VERSION ""

NS_ :

BS_:

BU_: VCU BMS Motor1 Motor2 CCU SCG

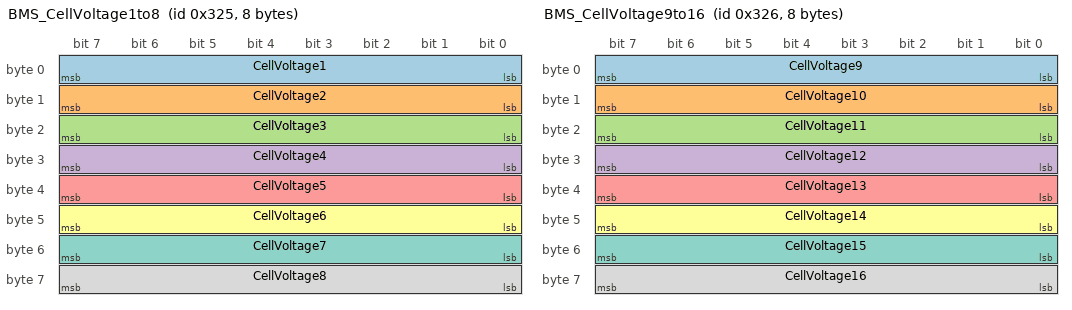
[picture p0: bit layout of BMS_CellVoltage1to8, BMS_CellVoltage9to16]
BO_ 805 BMS_CellVoltage1to8: 8 BMS
 SG_ CellVoltage1 : 0|8@1+ (0.02,0) [0|4.5] "" Vector__XXX
 SG_ CellVoltage2 : 8|8@1+ (0.02,0) [0|4.5] "" Vector__XXX
 SG_ CellVoltage3 : 16|8@1+ (0.02,0) [0|4.5] "" Vector__XXX
 SG_ CellVoltage4 : 24|8@1+ (0.02,0) [0|4.5] "" Vector__XXX
 SG_ CellVoltage5 : 32|8@1+ (0.02,0) [0|4.5] "" Vector__XXX
 SG_ CellVoltage6 : 40|8@1+ (0.02,0) [0|4.5] "" Vector__XXX
 SG_ CellVoltage7 : 48|8@1+ (0.02,0) [0|4.5] "" Vector__XXX
 SG_ CellVoltage8 : 56|8@1+ (0.02,0) [0|4.5] "" Vector__XXX

BO_ 806 BMS_CellVoltage9to16: 8 BMS
 SG_ CellVoltage9 : 0|8@1+ (0.02,0) [0|4.5] "" Vector__XXX
 SG_ CellVoltage10 : 8|8@1+ (0.02,0) [0|4.5] "" Vector__XXX
 SG_ CellVoltage11 : 16|8@1+ (0.02,0) [0|4.5] "" Vector__XXX
 SG_ CellVoltage12 : 24|8@1+ (0.02,0) [0|4.5] "" Vector__XXX
 SG_ CellVoltage13 : 32|8@1+ (0.02,0) [0|4.5] "" Vector__XXX
 SG_ CellVoltage14 : 40|8@1+ (0.02,0) [0|4.5] "" Vector__XXX
 SG_ CellVoltage15 : 48|8@1+ (0.02,0) [0|4.5] "" Vector__XXX
 SG_ CellVoltage16 : 56|8@1+ (0.02,0) [0|4.5] "" Vector__XXX

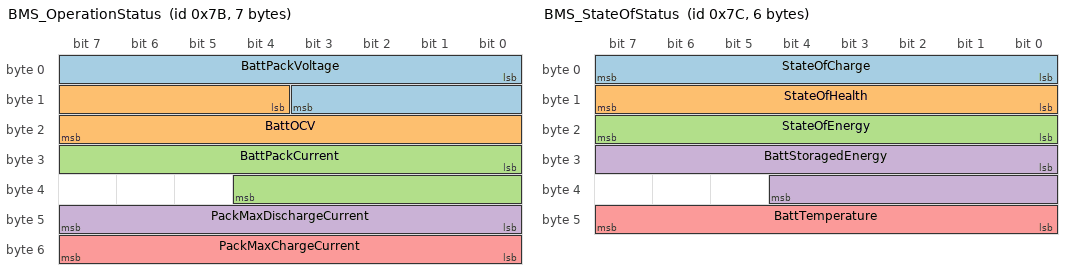
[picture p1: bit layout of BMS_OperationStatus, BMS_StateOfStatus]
BO_ 123 BMS_OperationStatus: 7 BMS
 SG_ BattPackVoltage : 0|12@1+ (0.02,0) [0|60] "V" Vector__XXX
 SG_ BattOCV : 12|12@1+ (0.02,0) [0|60] "V" Vector__XXX
 SG_ BattPackCurrent : 24|13@1+ (0.1,-409.6) [-250|250] "A" Vector__XXX
 SG_ PackMaxDischargeCurrent : 40|8@1+ (1,0) [0|250] "A" Vector__XXX
 SG_ PackMaxChargeCurrent : 48|8@1+ (1,0) [0|250] "A" Vector__XXX

BO_ 124 BMS_StateOfStatus: 6 BMS
 SG_ StateOfCharge : 0|8@1+ (0.5,0) [0|100] "%" Vector__XXX
 SG_ StateOfHealth : 8|8@1+ (0.5,0) [0|100] "%" Vector__XXX
 SG_ StateOfEnergy : 16|8@1+ (0.5,0) [0|100] "%" Vector__XXX
 SG_ BattStoragedEnergy : 24|13@1+ (1,0) [0|6000] "kWh" Vector__XXX
 SG_ BattTemperature : 40|8@1+ (0.5,-10) [-10|100] "%" Vector__XXX

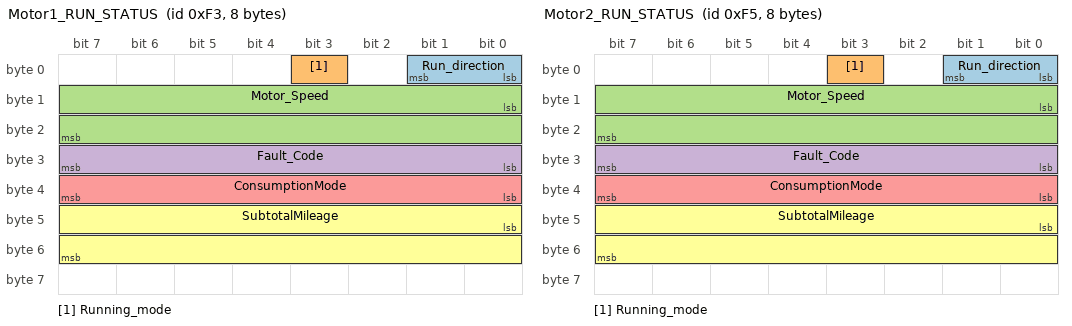
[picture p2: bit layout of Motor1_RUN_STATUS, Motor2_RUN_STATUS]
BO_ 243 Motor1_RUN_STATUS: 8 Motor1
 SG_ Run_direction : 0|2@1+ (1,0) [0|0] ""  VCU
 SG_ Running_mode : 3|1@1+ (1,0) [0|0] ""  VCU
 SG_ Motor_Speed : 8|16@1- (1,0) [0|0] "rpm"  VCU
 SG_ Fault_Code : 24|8@1+ (1,0) [0|0] ""  VCU
 SG_ ConsumptionMode : 32|8@1+ (1,0) [0|0] ""  VCU
 SG_ SubtotalMileage : 40|16@1+ (0.1,0) [0|0] "km"  VCU

BO_ 244 Motor1_ELEC_STATUS: 8 Motor1
 SG_ DC_LinkVoltage : 0|16@1- (0.1,0) [0|0] "V"  VCU
 SG_ DC_LinkCurrent : 16|16@1- (0.1,0) [0|0] "A"  VCU

BO_ 245 Motor2_RUN_STATUS: 8 Motor2
 SG_ Run_direction : 0|2@1+ (1,0) [0|0] ""  VCU
 SG_ Running_mode : 3|1@1+ (1,0) [0|0] ""  VCU
 SG_ Motor_Speed : 8|16@1- (1,0) [0|0] "rpm"  VCU
 SG_ Fault_Code : 24|8@1+ (1,0) [0|0] ""  VCU
 SG_ ConsumptionMode : 32|8@1+ (1,0) [0|0] ""  VCU
 SG_ SubtotalMileage : 40|16@1+ (0.1,0) [0|0] "km"  VCU

BO_ 246 Motor2_ELEC_STATUS: 8 Motor2
 SG_ DC_LinkVoltage : 0|16@1- (0.1,0) [0|0] "V"  VCU
 SG_ DC_LinkCurrent : 16|16@1- (0.1,0) [0|0] "A"  VCU

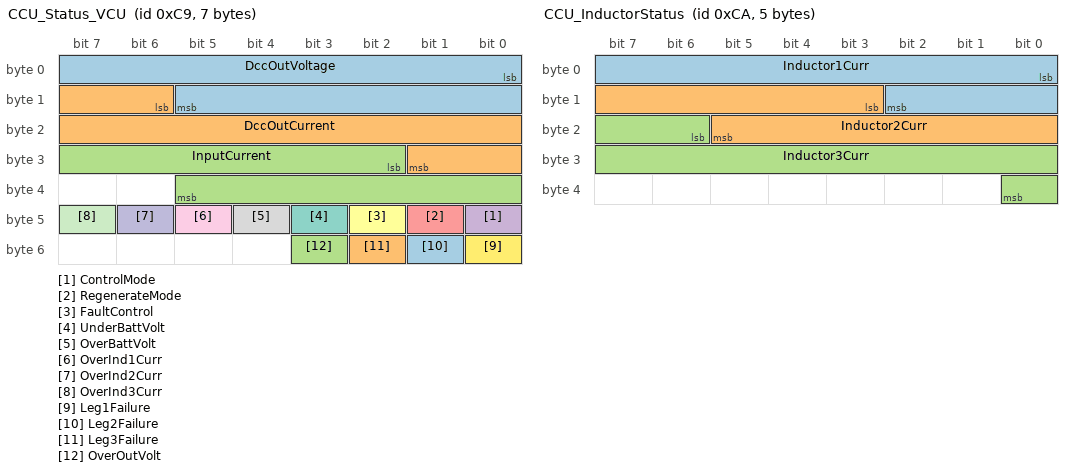
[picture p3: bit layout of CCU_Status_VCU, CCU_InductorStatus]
BO_ 201 CCU_Status_VCU: 7 CCU
 SG_ DccOutVoltage : 0|14@1+ (0.01,0) [0|130] "V" Vector__XXX
 SG_ DccOutCurrent : 14|12@1+ (0.1,-204.8) [-200|200] "A" Vector__XXX
 SG_ InputCurrent : 26|12@1+ (0.1,-204.8) [-200|200] "A" Vector__XXX
 SG_ ControlMode : 40|1@1+ (1,0) [0|0] "" Vector__XXX
 SG_ RegenerateMode : 41|1@1+ (1,0) [0|0] "" Vector__XXX
 SG_ FaultControl : 42|1@1+ (1,0) [0|0] "" Vector__XXX
 SG_ UnderBattVolt : 43|1@1+ (1,0) [0|0] "" Vector__XXX
 SG_ OverBattVolt : 44|1@1+ (1,0) [0|0] "" Vector__XXX
 SG_ OverInd1Curr : 45|1@1+ (1,0) [0|0] "" Vector__XXX
 SG_ OverInd2Curr : 46|1@1+ (1,0) [0|0] "" Vector__XXX
 SG_ OverInd3Curr : 47|1@1+ (1,0) [0|0] "" Vector__XXX
 SG_ Leg1Failure : 48|1@1+ (1,0) [0|0] "" Vector__XXX
 SG_ Leg2Failure : 49|1@1+ (1,0) [0|0] "" Vector__XXX
 SG_ Leg3Failure : 50|1@1+ (1,0) [0|0] "" Vector__XXX
 SG_ OverOutVolt : 51|1@1+ (1,0) [0|0] "" Vector__XXX

BO_ 202 CCU_InductorStatus: 5 CCU
 SG_ Inductor1Curr : 0|11@1+ (0.1,-102.4) [-100|100] "A" Vector__XXX
 SG_ Inductor2Curr : 11|11@1+ (0.1,-102.4) [-100|100] "A" Vector__XXX
 SG_ Inductor3Curr : 22|11@1+ (0.1,-102.4) [-100|100] "A" Vector__XXX

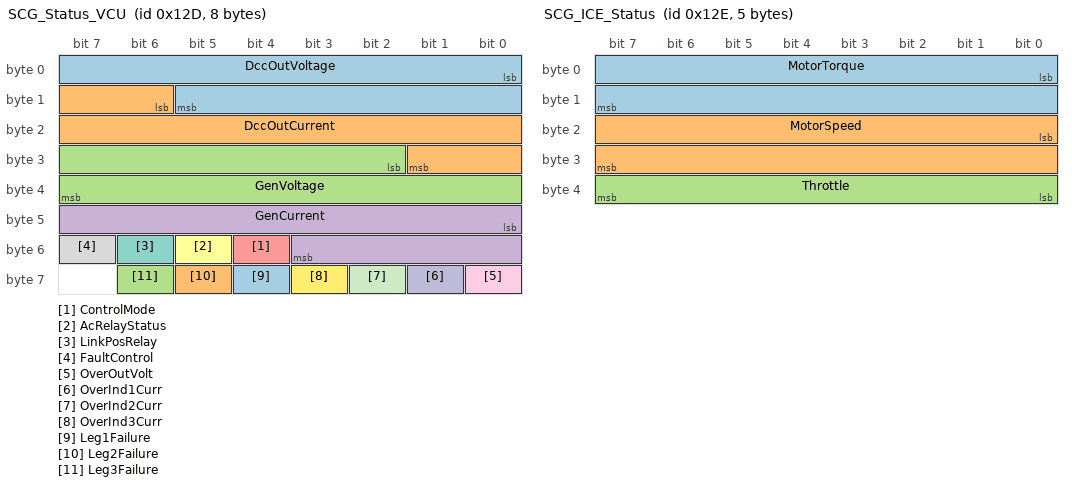
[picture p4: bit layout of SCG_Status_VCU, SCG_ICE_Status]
BO_ 301 SCG_Status_VCU: 8 SCG
 SG_ DccOutVoltage : 0|14@1+ (0.01,0) [0|130] "V" Vector__XXX
 SG_ DccOutCurrent : 14|12@1+ (0.1,-204.8) [-200|200] "A" Vector__XXX
 SG_ GenVoltage : 26|14@1+ (0.01,0) [0|130] "V" Vector__XXX
 SG_ GenCurrent : 40|12@1+ (0.1,-204.8) [-200|200] "A" Vector__XXX
 SG_ ControlMode : 52|1@1+ (1,0) [0|0] "" Vector__XXX
 SG_ AcRelayStatus : 53|1@1+ (1,0) [0|0] "" Vector__XXX
 SG_ LinkPosRelay : 54|1@1+ (1,0) [0|0] "" Vector__XXX
 SG_ FaultControl : 55|1@1+ (1,0) [0|0] "" Vector__XXX
 SG_ OverOutVolt : 56|1@1+ (1,0) [0|0] "" Vector__XXX
 SG_ OverInd1Curr : 57|1@1+ (1,0) [0|0] "" Vector__XXX
 SG_ OverInd2Curr : 58|1@1+ (1,0) [0|0] "" Vector__XXX
 SG_ OverInd3Curr : 59|1@1+ (1,0) [0|0] "" Vector__XXX
 SG_ Leg1Failure : 60|1@1+ (1,0) [0|0] "" Vector__XXX
 SG_ Leg2Failure : 61|1@1+ (1,0) [0|0] "" Vector__XXX
 SG_ Leg3Failure : 62|1@1+ (1,0) [0|0] "" Vector__XXX

BO_ 302 SCG_ICE_Status: 5 SCG
 SG_ MotorTorque : 0|16@1+ (1,-5000) [-5000|5000] "Nm" Vector__XXX
 SG_ MotorSpeed : 16|16@1+ (1,-15000) [-15000|15000] "rpm" Vector__XXX
 SG_ Throttle : 32|8@1+ (1,0) [0|0] "" Vector__XXX

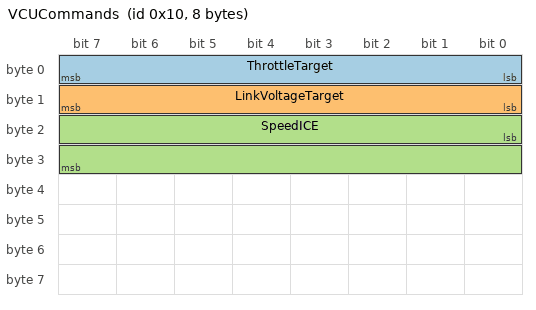
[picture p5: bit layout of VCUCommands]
BO_ 16 VCUCommands: 8 VCU
 SG_ ThrottleTarget : 0|8@1+ (0.5,0) [0|100] "%" Vector__XXX
 SG_ LinkVoltageTarget : 8|8@1+ (0.2,70) [70|120] "V" Vector__XXX
 SG_ SpeedICE : 16|16@1+ (1,0) [0|0] "rpm" Vector__XXX

BA_DEF_ SG_  "GenSigSendType" ENUM  "Cyclic","OnWrite","OnWriteWithRepetition","OnChange","OnChangeWithRepetition","IfActive","IfActiveWithRepetition";
BA_DEF_ SG_  "GenSigEnvVarType" ENUM  "int","float","undef";
BA_DEF_ BO_  "GenMsgILSupport" ENUM  "No","Yes";
BA_DEF_ BO_  "GenMsgCycleTimeFast" INT 2 100000;
BA_DEF_ BO_  "GenMsgSendType" ENUM  "Cyclic","not_used","not_used","not_used","not_used","Cyclic","not_used","IfActive";
BA_DEF_ BO_  "GenMsgCycleTime" INT 2 50000;
BA_DEF_ BO_  "GenMsgDelayTime" INT 1 1000;
BA_DEF_ BU_  "TpAddressingMode" INT 0 3;
BA_DEF_ BU_  "ILUsed" ENUM  "Yes","No";
BA_DEF_ BU_  "TpTxIdentifier" HEX 0 536870911;
BA_DEF_ BU_  "TpRxIdentifier" HEX 0 536870911;
BA_DEF_ BU_  "TpRxMask" HEX 0 65535;
BA_DEF_ BU_  "TpCanBus" INT 1 2;
BA_DEF_ BU_  "TpUseFC" INT 0 1;
BA_DEF_ BU_  "TpNodeBaseAddress" HEX 0 33554431;
BA_DEF_  "DBName" STRING ;
BA_DEF_  "GenEnvVarEndingDsp" STRING ;
BA_DEF_  "GenEnvVarEndingSnd" STRING ;
BA_DEF_  "GenEnvVarPrefix" STRING ;
BA_DEF_  "NmBaseAddress" HEX 1024 1055;
BA_DEF_  "GenNWMApCanOff" STRING ;
BA_DEF_  "GenNWMApCanOn" STRING ;
BA_DEF_  "GenNWMApCanSleep" STRING ;
BA_DEF_  "GenNWMGotoMode_Awake" STRING ;
BA_DEF_  "GenNWMGotoMode_BusSleep" STRING ;
BA_DEF_  "GenNWMTalkNM" STRING ;
BA_DEF_DEF_  "GenSigSendType" "Cyclic";
BA_DEF_DEF_  "GenSigEnvVarType" "undef";
BA_DEF_DEF_  "GenMsgILSupport" "Yes";
BA_DEF_DEF_  "GenMsgCycleTimeFast" 100;
BA_DEF_DEF_  "GenMsgSendType" "not_used";
BA_DEF_DEF_  "GenMsgCycleTime" 2;
BA_DEF_DEF_  "GenMsgDelayTime" 1;
BA_DEF_DEF_  "TpAddressingMode" 1;
BA_DEF_DEF_  "ILUsed" "Yes";
BA_DEF_DEF_  "TpTxIdentifier" 1;
BA_DEF_DEF_  "TpRxIdentifier" 1;
BA_DEF_DEF_  "TpRxMask" 255;
BA_DEF_DEF_  "TpCanBus" 1;
BA_DEF_DEF_  "TpUseFC" 1;
BA_DEF_DEF_  "TpNodeBaseAddress" 1536;
BA_DEF_DEF_  "DBName" "";
BA_DEF_DEF_  "GenEnvVarEndingDsp" "Dsp_";
BA_DEF_DEF_  "GenEnvVarEndingSnd" "_";
BA_DEF_DEF_  "GenEnvVarPrefix" "Env";
BA_DEF_DEF_  "NmBaseAddress" 1024;
BA_DEF_DEF_  "GenNWMApCanOff" "apCanOff()";
BA_DEF_DEF_  "GenNWMApCanOn" "apCanOn()";
BA_DEF_DEF_  "GenNWMApCanSleep" "apCanSleep()";
BA_DEF_DEF_  "GenNWMGotoMode_Awake" "GotoMode_Awake()";
BA_DEF_DEF_  "GenNWMGotoMode_BusSleep" "GotoMode_BusSleep()";
BA_DEF_DEF_  "GenNWMTalkNM" "TalkNM()";
BA_ "DBName" "EV_Demo";
BA_ "GenMsgSendType" BO_ 243 0;
BA_ "GenMsgCycleTime" BO_ 243 50;
BA_ "GenMsgSendType" BO_ 244 0;
BA_ "GenMsgCycleTime" BO_ 244 50;
BA_ "GenMsgSendType" BO_ 245 0;
BA_ "GenMsgCycleTime" BO_ 245 50;
BA_ "GenMsgSendType" BO_ 246 0;
BA_ "GenMsgCycleTime" BO_ 246 50;
BA_ "GenMsgSendType" BO_ 16 0;
BA_ "GenMsgCycleTime" BO_ 16 20;
VAL_ 243 Run_direction 0 "invalid" 1 "forward" 2 "back" ;
VAL_ 243 Running_mode 1 "Low_speed" 0 "High_speed" ;
VAL_ 243 Fault_Code 0 "no_fault" 1 "High pedal fault" 2 "Pre charge fault" 3 "Over current" 4 "Controller overheating" 6 "current sampling circuit fault" 8 "BMS fault" 9 "Battery under voltage" 10 "Battery over voltage" 11 "Motor overheating" 12 "Accelerator fault" ;
VAL_ 245 Run_direction 0 "invalid" 1 "forward" 2 "back" ;
VAL_ 245 Running_mode 1 "Low_speed" 0 "High_speed" ;
VAL_ 245 Fault_Code 0 "no_fault" 1 "High pedal fault" 2 "Pre charge fault" 3 "Over current" 4 "Controller overheating" 6 "current sampling circuit fault" 8 "BMS fault" 9 "Battery under voltage" 10 "Battery over voltage" 11 "Motor overheating" 12 "Accelerator fault" ;
